# H6 register map
Vendor: Allwinner; Series: H6; File version: 0.1
CPU: CA53 0, little endian, MPU, no FPU, 0 interrupt priority bits
Registers are 32-bit, read-write, reset 0x0 unless marked. A register's access mark holds for its fields unless they carry their own. Offsets are from the block's base; [hi:lo] are bit positions; {n}, {i} and the like mark numbered series; 'fields as' and 'values as' point back to an identical list.

## PIO
Base 0x07022000
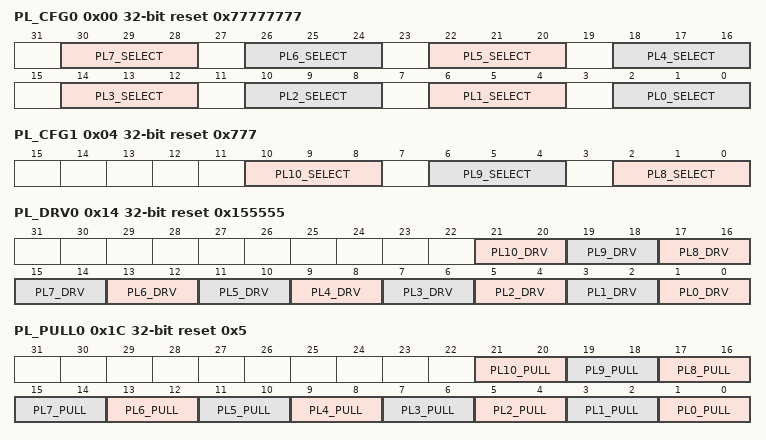
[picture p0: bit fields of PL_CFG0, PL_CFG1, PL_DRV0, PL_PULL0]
0x00 PL_CFG0 reset 0x77777777
  [30:28] PL7_SELECT — 000:Input 001:Output 010:S_JTAG_DI 011:Reserved 100:Reserved 101:Reserved 110:S_PL_EINT7 111:IO Disable
  [26:24] PL6_SELECT — 000:Input 001:Output 010:S_JTAG_DO 011:Reserved 100:Reserved 101:Reserved 110:S_PL_EINT6 111:IO Disable
  [22:20] PL5_SELECT — 000:Input 001:Output 010:S_JTAG_CK 011:Reserved 100:Reserved 101:Reserved 110:S_PL_EINT5 111:IO Disable
  [18:16] PL4_SELECT — 000:Input 001:Output 010:S_JTAG_MS 011:Reserved 100:Reserved 101:Reserved 110:S_PL_EINT4 111:IO Disable
  [14:12] PL3_SELECT — 000:Input 001:Output 010:S_UART_RX 011:Reserved 100:Reserved 101:Reserved 110:S_PL_EINT3 111:IO Disable
  [10:8] PL2_SELECT — 000:Input 001:Output 010:S_UART_TX 011:Reserved 100:Reserved 101:Reserved 110:S_PL_EINT2 111:IO Disable
  [6:4] PL1_SELECT — 000:Input 001:Output 010:Reserved 011:S_TWI_SDA 100:Reserved 101:Reserved 110:S_PL_EINT1 111:IO Disable
  [2:0] PL0_SELECT — 000:Input 001:Output 010:Reserved 011:S_TWI_SCK 100:Reserved 101:Reserved 110:S_PL_EINT0 111:IO Disable
0x04 PL_CFG1 reset 0x777
  [10:8] PL10_SELECT — 000:Input 001:Output 010:S_OWC 011:S_PWM1 100:Reserved 101:Reserved 110:S_PL_EINT10 111:IO Disable
  [6:4] PL9_SELECT — 000:Input 001:Output 010:S_CIR_RX 011:Reserved 100:Reserved 101:Reserved 110:S_PL_EINT9 111:IO Disable
  [2:0] PL8_SELECT — 000:Input 001:Output 010:S_PWM0 011:Reserved 100:Reserved 101:Reserved 110:S_PL_EINT8 111:IO Disable
0x08 PL_CFG2 reset not defined
0x0C PL_CFG3 reset not defined
0x10 PL_DAT
  [10:0] PL_DAT — If the port is configured as input, the corresponding bit is the pin state. If the port is configured as output, the pin state is the same as the corresponding bit. The read bit value is the value setup by software. If the port is configured as functional pin, the undefined value will be read.
0x14 PL_DRV0 reset 0x155555
  [all] fields
    {v}=Level_{v} (v=0..3)
  [2n+1:2n] PL{n}_DRV (n=0..10) — PL{n} Multi-Driving Select 00: Level 0 01: Level 1 10: Level 2 11: Level 3
0x18 PL_DRV1 reset not defined
0x1C PL_PULL0 reset 0x5
  [all] fields
    0=Pull_minus_up_slash_down_disable (Pull-up/down disable); 1=Pull_minus_up (Pull-up); 2=Pull_minus_down (Pull-down)
  [2n+1:2n] PL{n}_PULL (n=0..10) — PL{n} Pull-up/down Select 00: Pull-up/down disable 01: Pull-up 10: Pull-down 11: Reserved
0x20 PL_PULL1 reset not defined
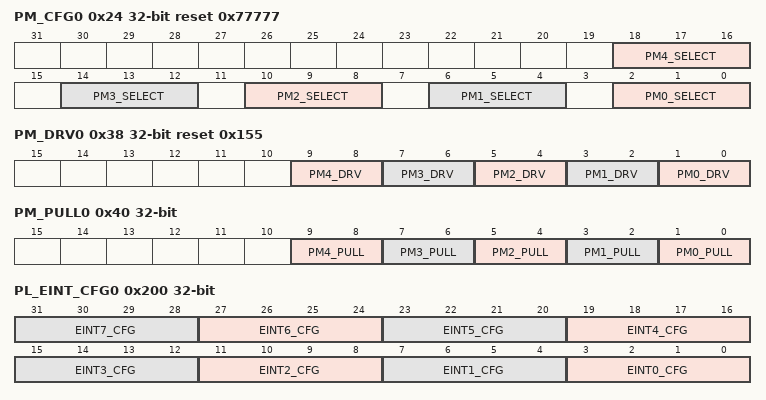
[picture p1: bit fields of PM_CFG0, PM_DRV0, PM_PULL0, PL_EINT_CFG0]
0x24 PM_CFG0 reset 0x77777
  [4n+2:4n] PM{n}_SELECT (n=0..4) — 000:Input 001:Output 010:Reserved 011:Reserved 100:Reserved 101:Reserved 110:S_PM_EINT{n} 111:IO Disable
{0x24+4i} PM_CFG{i} reset not defined (i=1..3)
0x34 PM_DAT
  [4:0] PM_DAT — If the port is configured as input, the corresponding bit is the pin state. If the port is configured as output, the pin state is the same as the corresponding bit. The read bit value is the value setup by software. If the port is configured as functional pin, the undefined value will be read.
0x38 PM_DRV0 reset 0x155
  [all] fields
    {v}=Level_{v} (v=0..3)
  [2n+1:2n] PM{n}_DRV (n=0..4) — PM{n} Multi-Driving Select 00: Level 0 01: Level 1 10: Level 2 11: Level 3
0x3C PM_DRV1 reset not defined
0x40 PM_PULL0
  [all] fields
    values as the fields of PL_PULL0
  [2n+1:2n] PM{n}_PULL (n=0..4) — PM{n} Pull-up/down Select 00: Pull-up/down disable 01: Pull-up 10: Pull-down 11: Reserved
0x44 PM_PULL1 reset not defined
0x200 PL_EINT_CFG0
  [all] fields
    0=Positive_Edge; 1=Negative_Edge; 2=High_Level; 3=Low_Level; 4=Double Edge (Positive/ Negative) Others: Reserved
  [4n+3:4n] EINT{n}_CFG (n=0..7) — External INT{n} Mode 0000: Positive Edge 0001: Negative Edge 0010: High Level 0011: Low Level 0100: Double Edge (Positive/ Negative) Others: Reserved
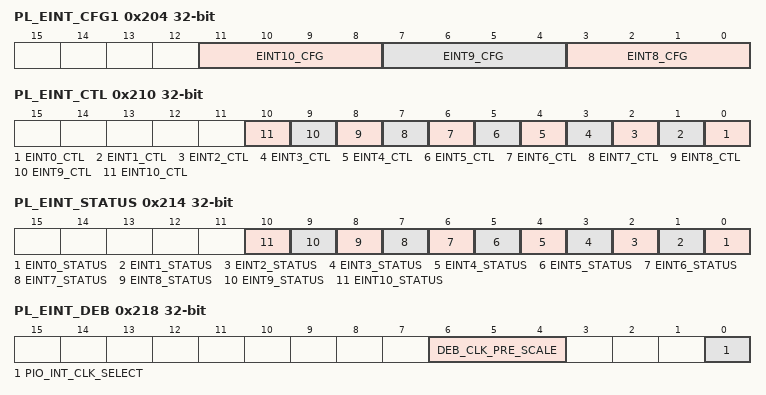
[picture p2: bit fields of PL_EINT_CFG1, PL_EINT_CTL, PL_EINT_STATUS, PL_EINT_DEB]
0x204 PL_EINT_CFG1
  [all] fields
    values as the fields of PL_EINT_CFG0
  [11:8] EINT10_CFG — External INT10 Mode 0000: Positive Edge 0001: Negative Edge 0010: High Level 0011: Low Level 0100: Double Edge (Positive/ Negative) Others: Reserved
  [7:4] EINT9_CFG — External INT9 Mode 0000: Positive Edge 0001: Negative Edge 0010: High Level 0011: Low Level 0100: Double Edge (Positive/ Negative) Others: Reserved
  [3:0] EINT8_CFG — External INT8 Mode 0000: Positive Edge 0001: Negative Edge 0010: High Level 0011: Low Level 0100: Double Edge (Positive/ Negative) Others: Reserved
0x208 PL_EINT_CFG2 reset not defined
0x20C PL_EINT_CFG3 reset not defined
0x210 PL_EINT_CTL
  [all] fields
    0=Disable; 1=Enable
  [n] EINT{n}_CTL (n=0..10) — External INT{n} Enable 0: Disable 1: Enable
0x214 PL_EINT_STATUS
  [all] fields
    0=No IRQ pending; 1=IRQ pending Write `1` to clear
  [n] EINT{n}_STATUS (n=0..10) — External INT{n} Pending Bit 0: No IRQ pending 1: IRQ pending Write `1` to clear
0x218 PL_EINT_DEB
  [6:4] DEB_CLK_PRE_SCALE — Debounce Clock Pre-scale n The selected clock source is prescaled by 2^n.
  [0] PIO_INT_CLK_SELECT — PIO Interrupt Clock Select 0: LOSC 32KHz 1: HOSC 24MHz
    0=LOSC (LOSC 32KHz); 1=HOSC (HOSC 24MHz)
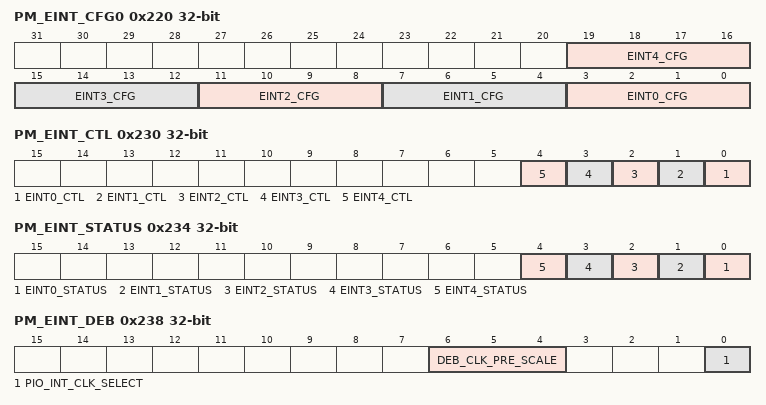
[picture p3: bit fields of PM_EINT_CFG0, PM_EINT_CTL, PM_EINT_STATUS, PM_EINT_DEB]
0x220 PM_EINT_CFG0
  [all] fields
    values as the fields of PL_EINT_CFG0
  [4n+3:4n] EINT{n}_CFG (n=0..4) — External INT{n} Mode 0000: Positive Edge 0001: Negative Edge 0010: High Level 0011: Low Level 0100: Double Edge (Positive/ Negative) Others: Reserved
{0x220+4i} PM_EINT_CFG{i} reset not defined (i=1..3)
0x230 PM_EINT_CTL
  [all] fields
    0=Disable; 1=Enable
  [n] EINT{n}_CTL (n=0..4) — External INT{n} Enable 0: Disable 1: Enable
0x234 PM_EINT_STATUS
  [all] fields
    0=No IRQ pending; 1=IRQ pending Write `1` to clear
  [n] EINT{n}_STATUS (n=0..4) — External INT{n} Pending Bit 0: No IRQ pending 1: IRQ pending Write `1` to clear
0x238 PM_EINT_DEB
  fields as PL_EINT_DEB
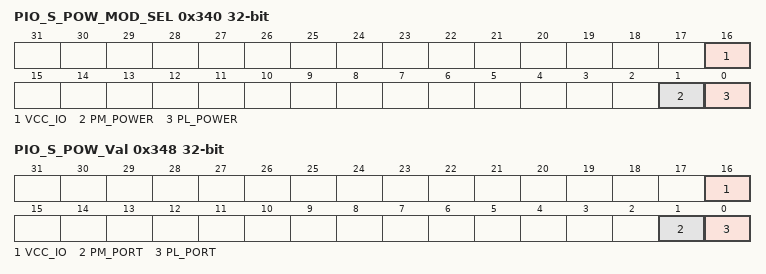
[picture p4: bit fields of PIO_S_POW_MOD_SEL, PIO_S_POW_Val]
0x340 PIO_S_POW_MOD_SEL
  [16] VCC_IO — POWER MODE Select 0: 3.3V 1: 1.8V
    0=_3_point_3V (3.3V); 1=_1_point_8V (1.8V)
  [1] PM_POWER — MODE Select 0: 3.3V 1: 1.8V If PM_Port Power Source selects VCC-IO,this bit is invalid
    0=_3_point_3V (3.3V); 1=_1_point_8V (1.8V If PM_Port Power Source selects VCC-IO,this bit is invalid)
  [0] PL_POWER — MODE Select 0: 3.3V 1: 1.8V If PL_Port Power Source selects VCC-IO,this bit is invalid
    0=_3_point_3V (3.3V); 1=_1_point_8V (1.8V If PL_Port Power Source selects VCC-IO,this bit is invalid)
0x348 PIO_S_POW_Val reset not defined
  [16] VCC_IO ro — Power Value
  [1] PM_PORT ro — Power Value If PM_Port Power Source selects VCC-IO,this bit is invalid
  [0] PL_PORT ro — Power Value If PL_Port Power Source selects VCC-IO,this bit is invalid
